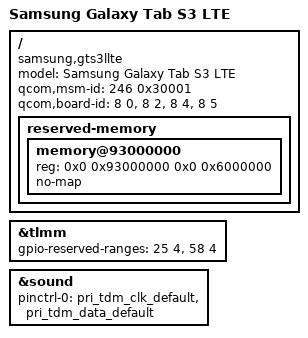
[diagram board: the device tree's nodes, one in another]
// SPDX-License-Identifier: BSD-3-Clause
/*
 * Samsung Galaxy Tab S3 LTE (SM-T825), codename gts3llte: the Wi-Fi model's
 * board with an MSM8996 (msm-id 246) instead of the APQ8096, plus the modem.
 * Everything else is shared with apq8096-samsung-gts3lwifi.dts; one kernel
 * and one device package boot both, lk2nd picks the device tree by its
 * compatible.
 *
 * The firmware regions use the Wi-Fi model's DT, the stock layout of both
 * models: the SM-T825's full LTE modem image (T825XXU3CTA1) loads into the
 * same 108 MiB modem region as the SM-T820's GNSS-only one, and the stock
 * SM-T825 DTs (Rev00-05) place modem, peripheral and MBA memory exactly as
 * the Wi-Fi model's. The modem DSP (MSS) boots its own image from the
 * tablet's modem partition (gts3-firmware), as on the SM-T820. The modem's
 * shared memory region, which stock lends to the modem through memshare
 * (no mainline driver), stays reserved.
 *
 * TLMM 58-61 stay reserved: stock comments out the eSE SPI on both models
 * and they are free on the Wi-Fi model, but which pins TrustZone owns is
 * set by its firmware and an owned pin resets the tablet about 9 s into
 * boot. So the top speaker pair (quaternary TDM on those pins) is left out
 * until it is checked on an SM-T825; the bottom pair, headphones and
 * microphones stay.
 */

#include "apq8096-samsung-gts3lwifi.dts"

/ {
	model = "Samsung Galaxy Tab S3 LTE";
	compatible = "samsung,gts3llte", "qcom,msm8996";

	qcom,msm-id = <246 0x30001>;
	/* Board revisions Rev00/02/04/05, as in the stock gts3llte DTs */
	qcom,board-id = <8 0>, <8 2>, <8 4>, <8 5>;

	reserved-memory {
		/* Downstream modem_shared_mem_region@0x93000000, LTE model only */
		memory@93000000 {
			reg = <0x0 0x93000000 0x0 0x6000000>;
			no-map;
		};
	};
};

&tlmm {
	/delete-property/ gpio-reserved-ranges;
	gpio-reserved-ranges = <25 4>, <58 4>;
};

&sound {
	pinctrl-0 = <&pri_tdm_clk_default>, <&pri_tdm_data_default>;

	/delete-node/ spk-top-dai-link;
};
